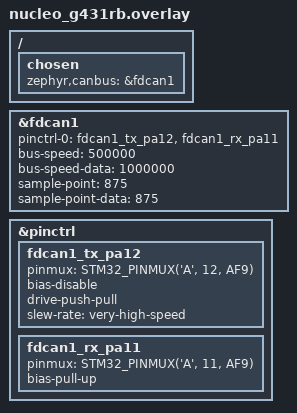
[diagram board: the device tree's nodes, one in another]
/*
 * Device tree overlay for CAN (FDCAN1) on STM32G431RB Nucleo
 * Pins: PA12 (TX), PA11 (RX)
 */

/ {
    chosen {
        zephyr,canbus = &fdcan1;  /* ← CORRECT! */
    };
};

/* enable CAN controller */
&fdcan1 {
    status = "okay";
    pinctrl-0 = <&fdcan1_tx_pa12 &fdcan1_rx_pa11>;
    pinctrl-names = "default";
    bus-speed = <500000>;           // Standard CAN bitrate (500 kbps)
    bus-speed-data = <1000000>;     // CAN FD data phase bitrate (1 Mbps)
    sample-point = <875>;           // Changed from 750 to 875 (87.5%)
    sample-point-data = <875>;      // Add this for CAN FD data phase
};

&pinctrl {
    fdcan1_tx_pa12: fdcan1_tx_pa12 {
        pinmux = <STM32_PINMUX('A', 12, AF9)>;
        bias-disable;
        drive-push-pull;
        slew-rate = "very-high-speed";  // Changed from "low-speed" for better signal integrity
    };

    fdcan1_rx_pa11: fdcan1_rx_pa11 {
        pinmux = <STM32_PINMUX('A', 11, AF9)>;
        bias-pull-up;  // Changed from bias-disable - pull-up is better for CAN RX
    };
};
